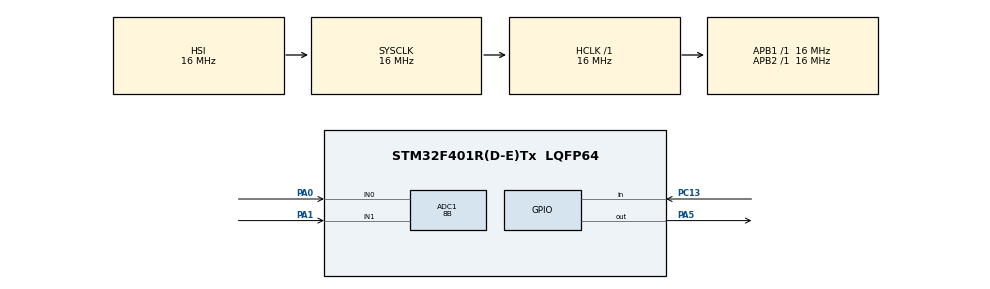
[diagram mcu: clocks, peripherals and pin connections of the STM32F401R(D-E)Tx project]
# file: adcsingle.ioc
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ADC1.NbrOfConversionFlag=1
ADC1.Resolution=ADC_RESOLUTION_8B
ADC1.SamplingTime-0\#ChannelRegularConversion=ADC_SAMPLETIME_28CYCLES
ADC1.master=1
Mcu.Family=STM32F4
Mcu.Name=STM32F401R(D-E)Tx
Mcu.Package=LQFP64
NVIC.PriorityGroup=NVIC_PRIORITYGROUP_4
PA0-WKUP.Signal=ADCx_IN0
PA1.Signal=ADCx_IN1
PA5.Signal=GPIO_Output
PC13-ANTI_TAMP.Signal=GPIO_Input
ProjectManager.HeapSize=0x200
ProjectManager.StackSize=0x400
ProjectManager.TargetToolchain=STM32CubeIDE
RCC.AHBFreq_Value=16000000
RCC.APB1Freq_Value=16000000
RCC.APB2Freq_Value=16000000
RCC.CortexFreq_Value=16000000
RCC.HSE_VALUE=25000000
RCC.HSI_VALUE=16000000
RCC.LSE_VALUE=32768
RCC.SYSCLKFreq_VALUE=16000000
RCC.VCOOutputFreq_Value=192000000
SH.ADCx_IN0.0=ADC1_IN0,IN0
SH.ADCx_IN1.0=ADC1_IN1,IN1
board=custom

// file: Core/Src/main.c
/* USER CODE BEGIN Header */
/**
  ******************************************************************************
  * @file           : main.c
  * @brief          : Main program body
  ******************************************************************************
  * @attention
  *
  * <h2><center>&copy; Copyright (c) 2021 STMicroelectronics.
  * All rights reserved.</center></h2>
  *
  * This software component is licensed by ST under BSD 3-Clause license,
  * the "License"; You may not use this file except in compliance with the
  * License. You may obtain a copy of the License at:
  *                        opensource.org/licenses/BSD-3-Clause
  *
  ******************************************************************************
  */
/* USER CODE END Header */
#include "main.h"

ADC_HandleTypeDef hadc1;

void SystemClock_Config(void);
static void MX_GPIO_Init(void);
static void MX_ADC1_Init(void);

//variables to store adc values
//one values for channel 0 and another for channel 1
//adc function return value of uint32_t
uint32_t adcchan0,adcchan1;
ADC_ChannelConfTypeDef sConfig = {0};//this has been taken from local declaration
int main(void)
{

  /* MCU Configuration--------------------------------------------------------*/

  /* Reset of all peripherals, Initializes the Flash interface and the Systick. */
  HAL_Init();

  /* Configure the system clock */
  SystemClock_Config();

  /* Initialize all configured peripherals */
  MX_GPIO_Init();
  MX_ADC1_Init();

  /* Infinite loop */
  while (1)
  {

    /* USER CODE BEGIN 3 */
	  //this code is for adc single conversion mode
	  //convert analogue to digital
	  //
	  sConfig.Channel=ADC_CHANNEL_0;//to swap channel 1 and 0
	  HAL_ADC_ConfigChannel(&hadc1, &sConfig);
//enable led pa5 snd pc13 push button
	  //enable adc input channel0 and channnel 1
	  //for neucleo u have single adc and 16 adc input
//at first do for single channel the swap
	  //for the configurations cahange resolution to 8 bit
	  //no of coersion to 1
	  //rank ..sampling time 28 cycle
	  HAL_ADC_Start(&hadc1);//it takes a  pointer
	  //wait for the end of conversion
	  // 5 is the timeout
	  //for single channel only start and get
	  if(HAL_ADC_PollForConversion(&hadc1,5)==HAL_OK){
		  adcchan0=HAL_ADC_GetValue(&hadc1);
	  }
	  sConfig.Channel=ADC_CHANNEL_1;
	  HAL_ADC_ConfigChannel(&hadc1, &sConfig);

	  HAL_ADC_Start(&hadc1);
	  if(HAL_ADC_PollForConversion(&hadc1,5)==HAL_OK){
		  adcchan1=HAL_ADC_GetValue(&hadc1);
	  }

//apply some delay
	  HAL_Delay(50);
  }
  /* USER CODE END 3 */
}

void SystemClock_Config(void)
{
  RCC_OscInitTypeDef RCC_OscInitStruct = {0};
  RCC_ClkInitTypeDef RCC_ClkInitStruct = {0};

  /** Configure the main internal regulator output voltage
  */
  __HAL_RCC_PWR_CLK_ENABLE();
  __HAL_PWR_VOLTAGESCALING_CONFIG(PWR_REGULATOR_VOLTAGE_SCALE2);
  /** Initializes the RCC Oscillators according to the specified parameters
  * in the RCC_OscInitTypeDef structure.
  */
  RCC_OscInitStruct.OscillatorType = RCC_OSCILLATORTYPE_HSI;
  RCC_OscInitStruct.HSIState = RCC_HSI_ON;
  RCC_OscInitStruct.HSICalibrationValue = RCC_HSICALIBRATION_DEFAULT;
  RCC_OscInitStruct.PLL.PLLState = RCC_PLL_NONE;
  if (HAL_RCC_OscConfig(&RCC_OscInitStruct) != HAL_OK)
  {
    Error_Handler();
  }
  /** Initializes the CPU, AHB and APB buses clocks
  */
  RCC_ClkInitStruct.ClockType = RCC_CLOCKTYPE_HCLK|RCC_CLOCKTYPE_SYSCLK
                              |RCC_CLOCKTYPE_PCLK1|RCC_CLOCKTYPE_PCLK2;
  RCC_ClkInitStruct.SYSCLKSource = RCC_SYSCLKSOURCE_HSI;
  RCC_ClkInitStruct.AHBCLKDivider = RCC_SYSCLK_DIV1;
  RCC_ClkInitStruct.APB1CLKDivider = RCC_HCLK_DIV1;
  RCC_ClkInitStruct.APB2CLKDivider = RCC_HCLK_DIV1;

  if (HAL_RCC_ClockConfig(&RCC_ClkInitStruct, FLASH_LATENCY_0) != HAL_OK)
  {
    Error_Handler();
  }
}

static void MX_ADC1_Init(void)
{

  //ADC_ChannelConfTypeDef sConfig = {0};

  /** Configure the global features of the ADC (Clock, Resolution, Data Alignment and number of conversion)
  */
  hadc1.Instance = ADC1;
  hadc1.Init.ClockPrescaler = ADC_CLOCK_SYNC_PCLK_DIV2;
  hadc1.Init.Resolution = ADC_RESOLUTION_8B;
  hadc1.Init.ScanConvMode = DISABLE;
  hadc1.Init.ContinuousConvMode = DISABLE;
  hadc1.Init.DiscontinuousConvMode = DISABLE;
  hadc1.Init.ExternalTrigConvEdge = ADC_EXTERNALTRIGCONVEDGE_NONE;
  hadc1.Init.ExternalTrigConv = ADC_SOFTWARE_START;
  hadc1.Init.DataAlign = ADC_DATAALIGN_RIGHT;
  hadc1.Init.NbrOfConversion = 1;
  hadc1.Init.DMAContinuousRequests = DISABLE;
  hadc1.Init.EOCSelection = ADC_EOC_SINGLE_CONV;
  if (HAL_ADC_Init(&hadc1) != HAL_OK)
  {
    Error_Handler();
  }
  /** Configure for the selected ADC regular channel its corresponding rank in the sequencer and its sample time.
  */
  sConfig.Channel = ADC_CHANNEL_0;
  sConfig.Rank = 1;
  sConfig.SamplingTime = ADC_SAMPLETIME_28CYCLES;
  if (HAL_ADC_ConfigChannel(&hadc1, &sConfig) != HAL_OK)
  {
    Error_Handler();
  }

}

static void MX_GPIO_Init(void)
{
  GPIO_InitTypeDef GPIO_InitStruct = {0};

  /* GPIO Ports Clock Enable */
  __HAL_RCC_GPIOC_CLK_ENABLE();
  __HAL_RCC_GPIOA_CLK_ENABLE();

  /*Configure GPIO pin Output Level */
  HAL_GPIO_WritePin(GPIOA, GPIO_PIN_5, GPIO_PIN_RESET);

  /*Configure GPIO pin : PC13 */
  GPIO_InitStruct.Pin = GPIO_PIN_13;
  GPIO_InitStruct.Mode = GPIO_MODE_INPUT;
  GPIO_InitStruct.Pull = GPIO_NOPULL;
  HAL_GPIO_Init(GPIOC, &GPIO_InitStruct);

  /*Configure GPIO pin : PA5 */
  GPIO_InitStruct.Pin = GPIO_PIN_5;
  GPIO_InitStruct.Mode = GPIO_MODE_OUTPUT_PP;
  GPIO_InitStruct.Pull = GPIO_NOPULL;
  GPIO_InitStruct.Speed = GPIO_SPEED_FREQ_LOW;
  HAL_GPIO_Init(GPIOA, &GPIO_InitStruct);

}

void Error_Handler(void)
{
  __disable_irq();
  while (1)
  {
  }
}

/************************ (C) COPYRIGHT STMicroelectronics *****END OF FILE****/
